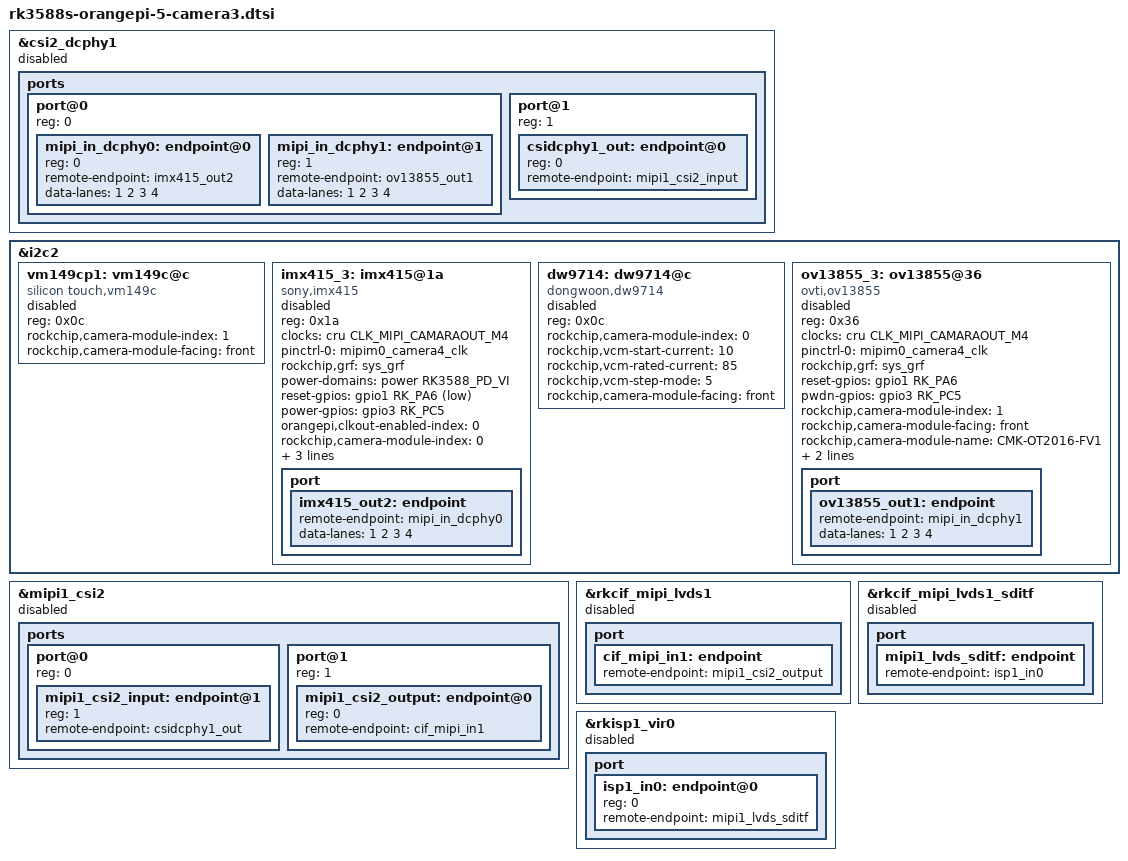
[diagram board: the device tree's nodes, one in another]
// SPDX-License-Identifier: (GPL-2.0+ OR MIT)
/*
 * Copyright (c) 2021 Rockchip Electronics Co., Ltd.
 *
 */

&csi2_dcphy1 {
	status = "disabled";

	ports {
		#address-cells = <1>;
		#size-cells = <0>;

		port@0 {
			reg = <0>;
			#address-cells = <1>;
			#size-cells = <0>;

			mipi_in_dcphy0: endpoint@0 {
				reg = <0>;
				remote-endpoint = <&imx415_out2>;
				data-lanes = <1 2 3 4>;
			};

			mipi_in_dcphy1: endpoint@1 {
				reg = <1>;
				remote-endpoint = <&ov13855_out1>;
				data-lanes = <1 2 3 4>;
			};
		};

		port@1 {
			reg = <1>;
			#address-cells = <1>;
			#size-cells = <0>;

			csidcphy1_out: endpoint@0 {
				reg = <0>;
				remote-endpoint = <&mipi1_csi2_input>;
			};
		};
	};
};

&i2c2 {
	status = "okay";

	vm149cp1: vm149c@c {
		compatible = "silicon touch,vm149c";
		status = "disabled";
		reg = <0x0c>;
		rockchip,camera-module-index = <1>;
		rockchip,camera-module-facing = "front";
	};

	imx415_3: imx415@1a {
		compatible = "sony,imx415";
		status = "disabled";
		reg = <0x1a>;
		clocks = <&cru CLK_MIPI_CAMARAOUT_M4>;
		clock-names = "xvclk";
		pinctrl-names = "default";
		pinctrl-0 = <&mipim0_camera4_clk>;
		rockchip,grf = <&sys_grf>;
		power-domains = <&power RK3588_PD_VI>;
		reset-gpios = <&gpio1 RK_PA6 GPIO_ACTIVE_LOW>;
		power-gpios = <&gpio3 RK_PC5 GPIO_ACTIVE_HIGH>;
		orangepi,clkout-enabled-index = <0>;
		rockchip,camera-module-index = <0>;
		rockchip,camera-module-facing = "back";
		rockchip,camera-module-name = "RADXA-CAMERA-4K";
		rockchip,camera-module-lens-name = "DEFAULT";
		port {
			imx415_out2: endpoint {
				remote-endpoint = <&mipi_in_dcphy0>;
				data-lanes = <1 2 3 4>;
			};
		};
	};

	dw9714: dw9714@c {
		compatible = "dongwoon,dw9714";
		status = "disabled";
		reg = <0x0c>;
		rockchip,camera-module-index = <0>;
		rockchip,vcm-start-current = <10>;
		rockchip,vcm-rated-current = <85>;
		rockchip,vcm-step-mode = <5>;
		rockchip,camera-module-facing = "front";
	};

	ov13855_3: ov13855@36 {
		compatible = "ovti,ov13855";
		status = "disabled";
		reg = <0x36>;
		clocks = <&cru CLK_MIPI_CAMARAOUT_M4>;
		clock-names = "xvclk";
		pinctrl-names = "default";
		pinctrl-0 = <&mipim0_camera4_clk>;
		rockchip,grf = <&sys_grf>;
		reset-gpios = <&gpio1 RK_PA6 GPIO_ACTIVE_HIGH>;
		pwdn-gpios = <&gpio3 RK_PC5 GPIO_ACTIVE_HIGH>;
		rockchip,camera-module-index = <1>;
		rockchip,camera-module-facing = "front";
		rockchip,camera-module-name = "CMK-OT2016-FV1";
		rockchip,camera-module-lens-name = "default";
		lens-focus = <&dw9714>;
		port {
			ov13855_out1: endpoint {
				remote-endpoint = <&mipi_in_dcphy1>;
				data-lanes = <1 2 3 4>;
			};
		};
	};
};

&mipi1_csi2 {
	status = "disabled";

	ports {
		#address-cells = <1>;
		#size-cells = <0>;

		port@0 {
			reg = <0>;
			#address-cells = <1>;
			#size-cells = <0>;

			mipi1_csi2_input: endpoint@1 {
				reg = <1>;
				remote-endpoint = <&csidcphy1_out>;
			};
		};

		port@1 {
			reg = <1>;
			#address-cells = <1>;
			#size-cells = <0>;

			mipi1_csi2_output: endpoint@0 {
				reg = <0>;
				remote-endpoint = <&cif_mipi_in1>;
			};
		};
	};
};

&rkcif_mipi_lvds1 {
	status = "disabled";

	port {
		cif_mipi_in1: endpoint {
			remote-endpoint = <&mipi1_csi2_output>;
		};
	};
};

&rkcif_mipi_lvds1_sditf {
	status = "disabled";

        port {
                mipi1_lvds_sditf: endpoint {
                        remote-endpoint = <&isp1_in0>;
                };
        };
};

&rkisp1_vir0 {
	status = "disabled";

	port {
		#address-cells = <1>;
		#size-cells = <0>;

		isp1_in0: endpoint@0 {
			reg = <0>;
			remote-endpoint = <&mipi1_lvds_sditf>;
		};
	};
};
